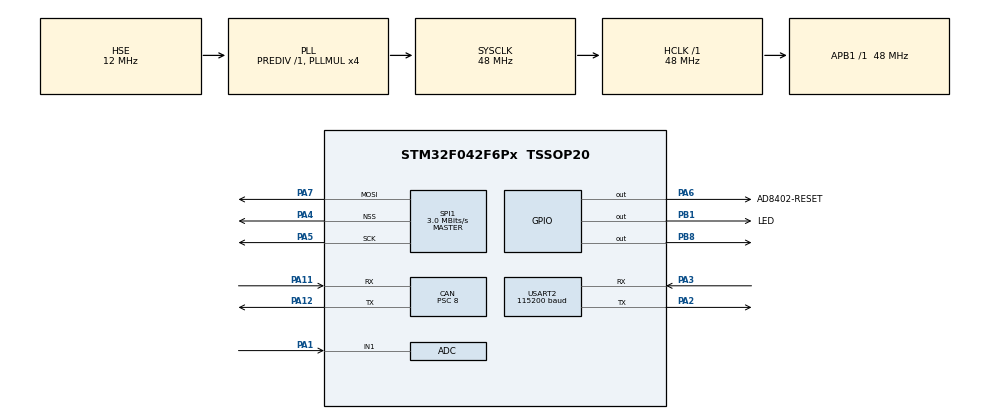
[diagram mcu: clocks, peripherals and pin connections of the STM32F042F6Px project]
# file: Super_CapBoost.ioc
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ADC.ClockPrescaler=ADC_CLOCK_SYNC_PCLK_DIV4
ADC.ContinuousConvMode=DISABLE
ADC.DMAContinuousRequests=DISABLE
ADC.DiscontinuousConvMode=ENABLE
ADC.EOCSelection=ADC_EOC_SEQ_CONV
ADC.SamplingTime=ADC_SAMPLETIME_13CYCLES_5
CAN.BS1=CAN_BS1_3TQ
CAN.BS2=CAN_BS2_2TQ
CAN.CalculateBaudRate=1000000
CAN.CalculateTimeBit=1000
CAN.CalculateTimeQuantum=166.66666666666666
CAN.Prescaler=8
CAN.TXFP=ENABLE
Dma.ADC.1.Direction=DMA_PERIPH_TO_MEMORY
Dma.ADC.1.Instance=DMA1_Channel1
Dma.ADC.1.MemDataAlignment=DMA_MDATAALIGN_WORD
Dma.ADC.1.MemInc=DMA_MINC_ENABLE
Dma.ADC.1.Mode=DMA_CIRCULAR
Dma.ADC.1.PeriphDataAlignment=DMA_PDATAALIGN_WORD
Dma.ADC.1.PeriphInc=DMA_PINC_DISABLE
Dma.ADC.1.Priority=DMA_PRIORITY_HIGH
Dma.Request0=USART2_RX
Dma.Request1=ADC
Dma.USART2_RX.0.Direction=DMA_PERIPH_TO_MEMORY
Dma.USART2_RX.0.Instance=DMA1_Channel5
Dma.USART2_RX.0.MemDataAlignment=DMA_MDATAALIGN_BYTE
Dma.USART2_RX.0.MemInc=DMA_MINC_ENABLE
Dma.USART2_RX.0.Mode=DMA_CIRCULAR
Dma.USART2_RX.0.PeriphDataAlignment=DMA_PDATAALIGN_BYTE
Dma.USART2_RX.0.PeriphInc=DMA_PINC_DISABLE
Dma.USART2_RX.0.Priority=DMA_PRIORITY_MEDIUM
FREERTOS.HEAP_NUMBER=4
FREERTOS.INCLUDE_uxTaskPriorityGet=0
FREERTOS.INCLUDE_vTaskDelete=0
FREERTOS.INCLUDE_vTaskPrioritySet=0
FREERTOS.Tasks01=defaultTask,0,64,StartDefaultTask,As weak,NULL,Dynamic,NULL,NULL;BoostControl,-3,200,BoostControlTask,As weak,NULL,Dynamic,NULL,NULL;LedShine,-3,64,LedShineTask,As weak,NULL,Dynamic,NULL,NULL;AdcOut,-3,64,AdcOutTask,As weak,NULL,Dynamic,NULL,NULL
FREERTOS.configMINIMAL_STACK_SIZE=64
FREERTOS.configTOTAL_HEAP_SIZE=2150
Mcu.Family=STM32F0
Mcu.Name=STM32F042F6Px
Mcu.Package=TSSOP20
NVIC.CEC_CAN_IRQn=true\:3\:0\:false\:false\:true\:true\:true\:true\:true
NVIC.DMA1_Channel1_IRQn=true\:3\:0\:true\:false\:true\:true\:true\:true\:true
NVIC.DMA1_Channel4_5_IRQn=true\:3\:0\:true\:false\:true\:true\:true\:true\:true
NVIC.TIM17_IRQn=true\:3\:0\:true\:false\:true\:false\:false\:true\:true
NVIC.TimeBase=TIM17_IRQn
NVIC.TimeBaseIP=TIM17
NVIC.USART2_IRQn=true\:3\:0\:false\:false\:true\:true\:true\:true\:true
PA1.Mode=IN1
PA1.Signal=ADC_IN1
PA11.Mode=CAN_Activate
PA11.Signal=CAN_RX
PA12.Mode=CAN_Activate
PA12.Signal=CAN_TX
PA13.Mode=Serial_Wire
PA13.Signal=SYS_SWDIO
PA14.Mode=Serial_Wire
PA14.Signal=SYS_SWCLK
PA2.Mode=Asynchronous
PA2.Signal=USART2_TX
PA3.Mode=Asynchronous
PA3.Signal=USART2_RX
PA4.Mode=NSS_Signal_Hard_Output
PA4.Signal=SPI1_NSS
PA5.Mode=TX_Only_Simplex_Unidirect_Master
PA5.Signal=SPI1_SCK
PA6.GPIO_Label=AD8402-RESET
PA6.GPIO_PuPd=GPIO_PULLUP
PA6.Signal=GPIO_Output
PA7.Mode=TX_Only_Simplex_Unidirect_Master
PA7.Signal=SPI1_MOSI
PB1.GPIO_Label=LED
PB1.Signal=GPIO_Output
PB8.GPIO_PuPd=GPIO_PULLDOWN
PB8.Signal=GPIO_Output
PF0-OSC_IN.Mode=HSE-External-Oscillator
PF0-OSC_IN.Signal=RCC_OSC_IN
PF1-OSC_OUT.Mode=HSE-External-Oscillator
PF1-OSC_OUT.Signal=RCC_OSC_OUT
ProjectManager.HeapSize=0x200
ProjectManager.StackSize=0x600
ProjectManager.TargetToolchain=MDK-ARM V5
RCC.AHBFreq_Value=48000000
RCC.APB1Freq_Value=48000000
RCC.APB1TimFreq_Value=48000000
RCC.HCLKFreq_Value=48000000
RCC.HSE_VALUE=12000000
RCC.PLLMUL=RCC_PLL_MUL4
RCC.PLLSourceVirtual=RCC_PLLSOURCE_HSE
RCC.SYSCLKFreq_VALUE=48000000
RCC.SYSCLKSource=RCC_SYSCLKSOURCE_PLLCLK
RCC.VDD_VALUE=3.3
SPI1.BaudRatePrescaler=SPI_BAUDRATEPRESCALER_16
SPI1.CLKPhase=SPI_PHASE_1EDGE
SPI1.CLKPolarity=SPI_POLARITY_LOW
SPI1.CalculateBaudRate=3.0 MBits/s
SPI1.DataSize=SPI_DATASIZE_10BIT
SPI1.Direction=SPI_DIRECTION_2LINES
SPI1.Mode=SPI_MODE_MASTER
SPI1.VirtualNSS=VM_NSSHARD
SPI1.VirtualType=VM_MASTER
USART2.BaudRate=115200
USART2.VirtualMode-Asynchronous=VM_ASYNC
VP_FREERTOS_VS_CMSIS_V1.Mode=CMSIS_V1
VP_SYS_VS_PINREMAP.Mode=PINREMAP
VP_SYS_VS_tim17.Mode=TIM17
board=custom

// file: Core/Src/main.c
/* USER CODE BEGIN Header */
/**
  ******************************************************************************
  * @file           : main.c
  * @brief          : Main program body
  ******************************************************************************
  * @attention
  *
  * <h2><center>&copy; Copyright (c) 2021 STMicroelectronics.
  * All rights reserved.</center></h2>
  *
  * This software component is licensed by ST under BSD 3-Clause license,
  * the "License"; You may not use this file except in compliance with the
  * License. You may obtain a copy of the License at:
  *                        opensource.org/licenses/BSD-3-Clause
  *
  ******************************************************************************
  */
/* USER CODE END Header */
#include "main.h"
#include "cmsis_os.h"
#include "adc.h"
#include "can.h"
#include "dma.h"
#include "spi.h"
#include "usart.h"
#include "gpio.h"

/* USER CODE BEGIN Includes */
#include"Boost_Control.h"

/* USER CODE END Includes */

/* USER CODE BEGIN PTD */

uint16_t num = 0;

/* USER CODE END PTD */

void SystemClock_Config(void);
void MX_FREERTOS_Init(void);

int main(void)
{

  /* MCU Configuration--------------------------------------------------------*/

  /* Reset of all peripherals, Initializes the Flash interface and the Systick. */
  HAL_Init();

  /* Configure the system clock */
  SystemClock_Config();

  /* USER CODE BEGIN SysInit */
  MX_DMA_Init();

  /* USER CODE END SysInit */

  /* Initialize all configured peripherals */
  MX_GPIO_Init();
  MX_SPI1_Init();
  MX_CAN_Init();
  MX_ADC_Init();
  MX_DMA_Init();
  MX_USART2_UART_Init();

  /* Call init function for freertos objects (in freertos.c) */
  MX_FREERTOS_Init();
  /* Start scheduler */
  osKernelStart();

  /* We should never get here as control is now taken by the scheduler */
  /* Infinite loop */
  while (1)
  {

    /* USER CODE BEGIN 3 */
		HAL_Delay(1);

  }
  /* USER CODE END 3 */
}

void SystemClock_Config(void)
{
  RCC_OscInitTypeDef RCC_OscInitStruct = {0};
  RCC_ClkInitTypeDef RCC_ClkInitStruct = {0};

  /** Initializes the RCC Oscillators according to the specified parameters
  * in the RCC_OscInitTypeDef structure.
  */
  RCC_OscInitStruct.OscillatorType = RCC_OSCILLATORTYPE_HSE;
  RCC_OscInitStruct.HSEState = RCC_HSE_ON;
  RCC_OscInitStruct.PLL.PLLState = RCC_PLL_ON;
  RCC_OscInitStruct.PLL.PLLSource = RCC_PLLSOURCE_HSE;
  RCC_OscInitStruct.PLL.PLLMUL = RCC_PLL_MUL4;
  RCC_OscInitStruct.PLL.PREDIV = RCC_PREDIV_DIV1;
  if (HAL_RCC_OscConfig(&RCC_OscInitStruct) != HAL_OK)
  {
    Error_Handler();
  }
  /** Initializes the CPU, AHB and APB buses clocks
  */
  RCC_ClkInitStruct.ClockType = RCC_CLOCKTYPE_HCLK|RCC_CLOCKTYPE_SYSCLK
                              |RCC_CLOCKTYPE_PCLK1;
  RCC_ClkInitStruct.SYSCLKSource = RCC_SYSCLKSOURCE_PLLCLK;
  RCC_ClkInitStruct.AHBCLKDivider = RCC_SYSCLK_DIV1;
  RCC_ClkInitStruct.APB1CLKDivider = RCC_HCLK_DIV1;

  if (HAL_RCC_ClockConfig(&RCC_ClkInitStruct, FLASH_LATENCY_1) != HAL_OK)
  {
    Error_Handler();
  }
}

void HAL_TIM_PeriodElapsedCallback(TIM_HandleTypeDef *htim)
{
  if (htim->Instance == TIM17) {
    HAL_IncTick();
  }
}

void Error_Handler(void)
{
  __disable_irq();
  while (1)
  {
  }
}

/************************ (C) COPYRIGHT STMicroelectronics *****END OF FILE****/

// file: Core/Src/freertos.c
/* USER CODE BEGIN Header */
/**
  ******************************************************************************
  * File Name          : freertos.c
  * Description        : Code for freertos applications
  ******************************************************************************
  * @attention
  *
  * <h2><center>&copy; Copyright (c) 2021 STMicroelectronics.
  * All rights reserved.</center></h2>
  *
  * This software component is licensed by ST under Ultimate Liberty license
  * SLA0044, the "License"; You may not use this file except in compliance with
  * the License. You may obtain a copy of the License at:
  *                             www.st.com/SLA0044
  *
  ******************************************************************************
  */
/* USER CODE END Header */

#include "FreeRTOS.h"
#include "task.h"
#include "main.h"
#include "cmsis_os.h"

osThreadId defaultTaskHandle;
osThreadId BoostControlHandle;
osThreadId LedShineHandle;
osThreadId AdcOutHandle;

void StartDefaultTask(void const * argument);
void BoostControlTask(void const * argument);
void LedShineTask(void const * argument);
void AdcOutTask(void const * argument);

void MX_FREERTOS_Init(void); /* (MISRA C 2004 rule 8.1) */

/* GetIdleTaskMemory prototype (linked to static allocation support) */
void vApplicationGetIdleTaskMemory( StaticTask_t **ppxIdleTaskTCBBuffer, StackType_t **ppxIdleTaskStackBuffer, uint32_t *pulIdleTaskStackSize );

/* USER CODE BEGIN GET_IDLE_TASK_MEMORY */
static StaticTask_t xIdleTaskTCBBuffer;
static StackType_t xIdleStack[configMINIMAL_STACK_SIZE];

void vApplicationGetIdleTaskMemory( StaticTask_t **ppxIdleTaskTCBBuffer, StackType_t **ppxIdleTaskStackBuffer, uint32_t *pulIdleTaskStackSize )
{
  *ppxIdleTaskTCBBuffer = &xIdleTaskTCBBuffer;
  *ppxIdleTaskStackBuffer = &xIdleStack[0];
  *pulIdleTaskStackSize = configMINIMAL_STACK_SIZE;
  /* place for user code */
}
/* USER CODE END GET_IDLE_TASK_MEMORY */

void MX_FREERTOS_Init(void) {

  /* Create the thread(s) */
  /* definition and creation of defaultTask */
  osThreadDef(defaultTask, StartDefaultTask, osPriorityNormal, 0, 64);
  defaultTaskHandle = osThreadCreate(osThread(defaultTask), NULL);

  /* definition and creation of BoostControl */
  osThreadDef(BoostControl, BoostControlTask, osPriorityIdle, 0, 200);
  BoostControlHandle = osThreadCreate(osThread(BoostControl), NULL);

  /* definition and creation of LedShine */
  osThreadDef(LedShine, LedShineTask, osPriorityIdle, 0, 64);
  LedShineHandle = osThreadCreate(osThread(LedShine), NULL);

  /* definition and creation of AdcOut */
  osThreadDef(AdcOut, AdcOutTask, osPriorityIdle, 0, 64);
  AdcOutHandle = osThreadCreate(osThread(AdcOut), NULL);

}

__weak void StartDefaultTask(void const * argument)
{
  for(;;)
  {
    osDelay(1);
  }
}

__weak void BoostControlTask(void const * argument)
{
  for(;;)
  {
    osDelay(1);
  }
}

__weak void LedShineTask(void const * argument)
{
  for(;;)
  {
    osDelay(1);
  }
}

__weak void AdcOutTask(void const * argument)
{
  for(;;)
  {
    osDelay(1);
  }
}

/************************ (C) COPYRIGHT STMicroelectronics *****END OF FILE****/
